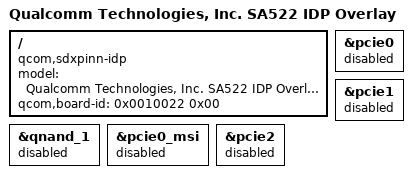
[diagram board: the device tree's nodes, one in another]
/dts-v1/;
/plugin/;

#include "sa522m-idp.dtsi"

/ {
	model = "Qualcomm Technologies, Inc. SA522 IDP Overlay";
	compatible = "qcom,sdxpinn-idp",
		"qcom,sdxpinn", "qcom,idp";
	qcom,board-id = <0x0010022 0x00>;
};

&qnand_1 {
	status = "disabled";
};

&pcie0 {
	status = "disabled";
};

&pcie0_msi {
	status = "disabled";
};

&pcie1 {
	status = "disabled";
};

&pcie2 {
	status = "disabled";
};
